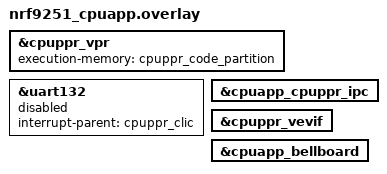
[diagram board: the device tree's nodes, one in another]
/*
 * Copyright (c) 2026 Nordic Semiconductor
 * SPDX-License-Identifier: LicenseRef-Nordic-5-Clause
 */

&cpuppr_vpr {
	execution-memory = <&cpuppr_code_partition>;
	/delete-property/ source-memory;
};

&uart132 {
	status = "reserved";
	interrupt-parent = <&cpuppr_clic>;
};

&cpuapp_cpuppr_ipc {
	status = "okay";
};

&cpuppr_vevif {
	status = "okay";
};

&cpuapp_bellboard {
	status = "okay";
};
